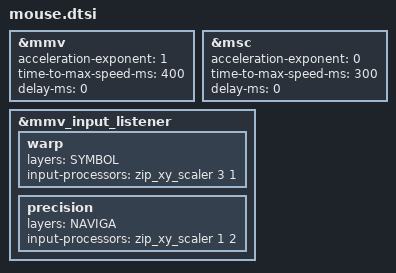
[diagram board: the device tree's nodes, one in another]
// Settings tuned for 3840 x 2160 display resolution
#define ZMK_POINTING_DEFAULT_MOVE_VAL 900 // 600
#define ZMK_POINTING_DEFAULT_SCRL_VAL 20  // 10

#include <dt-bindings/zmk/pointing.h>
#include <input/processors.dtsi>
#include <zephyr/dt-bindings/input/input-event-codes.h>

&mmv {
  acceleration-exponent = <1>;          // 1
  time-to-max-speed-ms = <400>;         // 300
  delay-ms = <0>;                       // 0
};

&msc {
  acceleration-exponent = <0>;          // 0
  time-to-max-speed-ms = <300>;         // 300
  delay-ms = <0>;                       // 0
};

&mmv_input_listener {
  warp {
    layers = <SYMBOL>;
    input-processors = <&zip_xy_scaler 3 1>;
  };
  precision {
    layers = <NAVIGA>;
    input-processors = <&zip_xy_scaler 1 2>;
  };
};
